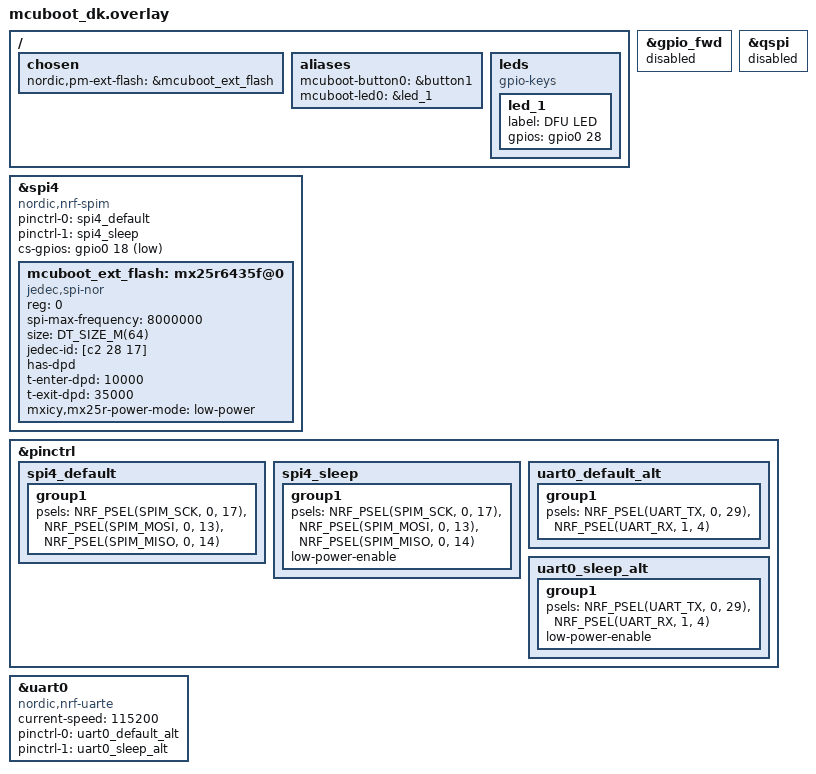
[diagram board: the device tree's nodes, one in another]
&gpio_fwd {
    status = "disabled";
};
&qspi {
    status = "disabled";
    /delete-node/ mx25r64;
};

&spi4 {
    compatible = "nordic,nrf-spim";
    status = "okay";
    pinctrl-0 = <&spi4_default>;
    pinctrl-1 = <&spi4_sleep>;
    pinctrl-names = "default", "sleep";
    cs-gpios = <&gpio0 18 GPIO_ACTIVE_LOW>;
 
    mcuboot_ext_flash: mx25r6435f@0 {
        compatible = "jedec,spi-nor";
        reg = <0>;
        spi-max-frequency = <8000000>;
        size = <DT_SIZE_M(64)>;
        jedec-id = [c2 28 17];
        has-dpd;
        t-enter-dpd = <10000>;
        t-exit-dpd = <35000>;
        mxicy,mx25r-power-mode = "low-power";
    };
};
/ {
	chosen {
        nordic,pm-ext-flash = &mcuboot_ext_flash;
    };
    aliases {
        mcuboot-button0 = &button1;
        mcuboot-led0 = &led_1;
    };
 
    leds {
        compatible = "gpio-keys";
 
        led_1: led_1 {
            label = "DFU LED";
            gpios = <&gpio0 28 GPIO_ACTIVE_HIGH>;
 
        };
    };
};

&pinctrl {
/* SPI pins for external flash */
   spi4_default: spi4_default {
        group1 {
            psels = <NRF_PSEL(SPIM_SCK,  0, 17)>,
                    <NRF_PSEL(SPIM_MOSI, 0, 13)>,
                    <NRF_PSEL(SPIM_MISO, 0, 14)>;
        };
    };
    spi4_sleep: spi4_sleep {
        group1 {
            psels = <NRF_PSEL(SPIM_SCK,  0, 17)>,
                    <NRF_PSEL(SPIM_MOSI, 0, 13)>,
                    <NRF_PSEL(SPIM_MISO, 0, 14)>;
            low-power-enable;
        };
    };
    uart0_default_alt: uart0_default_alt {
      group1 {
         psels = <NRF_PSEL(UART_TX, 0, 29)>,
				<NRF_PSEL(UART_RX, 1, 4)>;
      };
   };
   uart0_sleep_alt: uart0_sleep_alt {
      group1 {
         psels = <NRF_PSEL(UART_TX, 0, 29)>,
			     <NRF_PSEL(UART_RX, 1, 4)>;
         low-power-enable;
      };
   };
};

&uart0 {
   status = "okay";
   compatible = "nordic,nrf-uarte";
   current-speed = <115200>;
   pinctrl-0 = <&uart0_default_alt>;
   pinctrl-1 = <&uart0_sleep_alt>;
   pinctrl-names = "default", "sleep";
};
